# netx90_app register map
File version: 1.0
CPU: CM4 r0p1, little endian, MPU, FPU, 4 interrupt priority bits, 78 interrupts
Registers are 32-bit, read-write, reset 0x0 unless marked. A register's access mark holds for its fields unless they carry their own. Offsets are from the block's base; [hi:lo] are bit positions; {n}, {i} and the like mark numbered series; 'fields as' and 'values as' point back to an identical list; <NAME> marks a mode.

## xlink0
Base 0xFF900400
Same registers: xlink1 0xFF900410, xlink2 0xFF900420, xlink3 0xFF900430, xlink4 0xFF900440, xlink5 0xFF900450, xlink6 0xFF900460, xlink7 0xFF900470
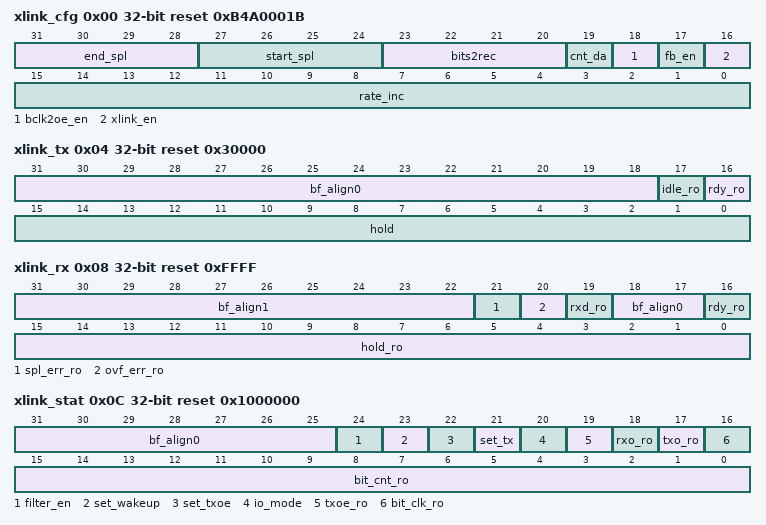
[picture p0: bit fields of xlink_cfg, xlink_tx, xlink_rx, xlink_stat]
0x00 xlink_cfg reset 0xB4A0001B — configuration register
  [31:28] end_spl — end sample point for receive data
  [27:24] start_spl — start sample point for receive data a sample period is defined as 1/16 of the bitrate period range: 0x0 - 0xf note: settings for start_spl and end_spl should always fulfill the condition: (start_spl < end_spl)
  [23:20] bits2rec — count of bits to receive note: the reset value expect: 1stopbit, 8databits, 1paritybit and 1stopbit
  [19] cnt_da — test feature, do not set this bit!
  [18] bclk2oe_en — test feature, do not set this bit!
  [17] fb_en — test feature, enable internal feedback
  [16] xlink_en — disable the output enable, and activity
  [15:0] rate_inc — bitrate compare value for bit clock counter (bit_cnt) BITRATE = 100e6/(rate_inc) typical settings for IOLINK: {| cols=4 BIT_RATE | rate_inc | clock period | calc: 1/BIT_RATE 4800 | 0x5160 | 208,33 us | 208,3333us 38400 | 0xa2b | 26,04 us | 26,04167us 230400 | 0x1b1 | 4,34 us | 4,340278us ... | | invalid: 0 | 0 | 0 | 0 }
0x04 xlink_tx reset 0x30000 (reset mask 0x3FFFF) — xlink transmit register
  [31:18] bf_align0 — bitField alignment value for aeabi compatibility
  [17] idle_ro — indicates no activity on tx
  [16] rdy_ro — TX buffer ready (valid on ready) 0 TX buffer not ready 1 TX buffer ready
  [15:0] hold — hold register format for a valid serial DATA sequence: <-ctrl.DATA-><------------------- serial DATA --------------------> { END_BIT:1 }[{STOPBIT:1}{DATABITS max. 12:0101..0010}{STARTBIT:0}] notes: ENDBIT is a hardware marker to stop the shifting, and will not be transmitted. this condition implied, than all other not used bits should be zero
0x08 xlink_rx reset 0xFFFF (reset mask 0x39FFFF) — xlink RX register writing to the register, reset the ready bit, the overflow bit and the sampling error bit
  [31:22] bf_align1 — bitField alignment value for aeabi compatibility
  [21] spl_err_ro — sampling error detected if the amount of sampled bits (HI or LOW) do not fulfill the condition: (end_spl - start_spl) < (count of HI/LOW bits)
  [20] ovf_err_ro — overflow error on received data
  [19] rxd_ro — current status of rx data
  [18:17] bf_align0 — bitField alignment value for aeabi compatibility
  [16] rdy_ro — RX buffer ready (valid on ready) 0 RX buffer not ready 1 RX buffer ready
  [15:0] hold_ro — RX byte (when valid) hold[15:0] is used to shift in RX(LSB first!) the amount of shifted bits is defined by bits2rec shift order is bit15 downto bit0
0x0C xlink_stat reset 0x1000000 (reset mask 0x1FFFFFF) — xlink status register & io control writing to this register set the bit clock counter to zero!
  [31:25] bf_align0 — bitField alignment value for aeabi compatibility
  [24] filter_en — enable 3 majority ruling filter
  [23] set_wakeup — set the wakeup port
  [22] set_txoe — set the tx output enable
  [21] set_tx — set the tx port,
  [20] io_mode — enable the io mode on tx and wakeup 0 : disable io function on tx, txoe, wakeup 1 : enable io function on tx, txoe, wakeup
  [19] txoe_ro — status of tx output enable
  [18] rxo_ro — status of rx input
  [17] txo_ro — status of tx output
  [16] bit_clk_ro — status of bit clock signal
  [15:0] bit_cnt_ro — status of bit clock counter

## io_link_irq
Base 0xFF900480
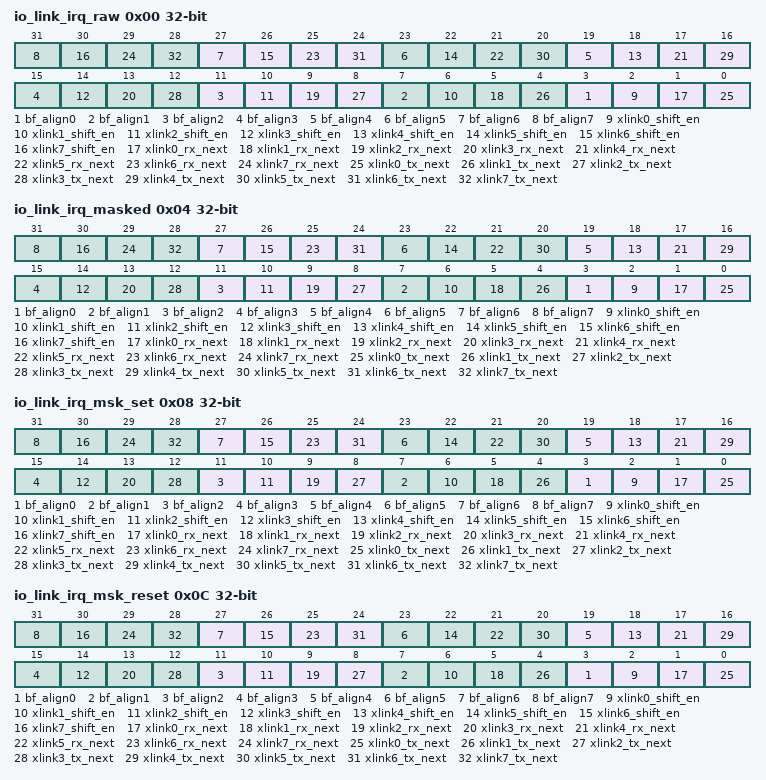
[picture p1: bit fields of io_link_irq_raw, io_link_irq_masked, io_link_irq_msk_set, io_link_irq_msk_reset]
0x00 io_link_irq_raw (reset mask 0x77777777) — IO-Link raw interrupts: Read access shows status of unmasked IRQs. IRQs are set automatically and reset by writing to this register: Write access with '1' resets the appropriate IRQ. Write access with '0' does not influence this bit.
  [4n+3] bf_align{n} (n=0..7) — bitField alignment value for aeabi compatibility
  [4n+2] xlink{n}_shift_en (n=0..7) — shift_en interrupt
  [4n+1] xlink{n}_rx_next (n=0..7) — rx_next interrupt
  [4n] xlink{n}_tx_next (n=0..7) — tx_next interrupt
0x04 io_link_irq_masked ro (reset mask 0x77777777) — IO-Link Masked IRQ register Shows status of masked IRQs (as connected to ARM/xPIC)
  fields as io_link_irq_raw
0x08 io_link_irq_msk_set (reset mask 0x77777777) — IO-Link interrupt mask enable: The IRQ mask enables interrupt requests for corresponding interrupt sources. As its bits might be changed by different software tasks, the IRQ mask register is not writable directly, but by set and reset masks: Write access with '1' sets interrupt mask bit (enables interrupt request for corresponding interrupt source). Write access with '0' does not influence this bit. Read access shows actual interrupt mask. Attention: Before activating interrupt mask, delete old pending interrupts by writing the same value to io_link_irq_raw.
  fields as io_link_irq_raw
0x0C io_link_irq_msk_reset (reset mask 0x77777777) — IO-Link interrupt mask disable: This is the corresponding reset mask to disable interrupt requests for corresponding interrupt sources: Write access with '1' resets interrupt mask bit (disables interrupt request for corresponding interrupt source). Write access with '0' does not influence this bit. Read access shows actual interrupt mask.
  fields as io_link_irq_raw
